# cyt2b6 register map
Vendor: Cypress Semiconductor; Series: cyt2b6; File version: 1.0
CPU: CM4 r0p1, little endian, MPU, FPU, VTOR, 3 interrupt priority bits
Registers are 32-bit, read-write, reset 0x0 unless marked. A register's access mark holds for its fields unless they carry their own. Offsets are from the block's base; [hi:lo] are bit positions; lines under a group give offsets from that group; {n}, {i} and the like mark numbered series; 'fields as' and 'values as' point back to an identical list; <NAME> marks a mode.

## SRSS (part 1 of 2) — SRSS Core Registers (ver2)
Base 0x40260000
0x40 PWR_LVD_STATUS ro — High Voltage / Low Voltage Detector (HVLVD) Status Register
  [0] HVLVD1_OUT — HVLVD1 output. 0: below voltage threshold 1: above voltage threshold
0x44 PWR_LVD_STATUS2 ro — High Voltage / Low Voltage Detector (HVLVD) Status Register #2
  [0] HVLVD2_OUT — HVLVD2 output. 0: below voltage threshold 1: above voltage threshold
{0x100+4i} CLK_DSI_SELECT[{i}] (i=0..15) — Clock DSI Select Register
  [4:0] DSI_MUX — Selects a DSI source or low frequency clock for use in a clock path. The output of this mux can be selected for clock PATH<i> using CLK_SELECT_PATH register. Using the output of this mux as HFCLK source will result in undefined behavior. It can be used to clocks to DSI or as reference inputs for the FLL/PLL, subject to the frequency limits of those circuits. This mux is not glitch free, so do not change the selection while it is an actively selected clock.
    {v}=DSI_OUT{v} (DSI{v} - dsi_out[{v}]) (v=0..15); 16=ILO0 (ILO0 - Internal Low-speed Oscillator #0); 17=WCO (WCO - Watch-Crystal Oscillator); 18=ALTLF (ALTLF - Alternate Low-Frequency Clock); 19=PILO (PILO - Precision Internal Low-speed Oscillator); 20=ILO1 (ILO1 - Internal Low-speed Oscillator #1, if present.)
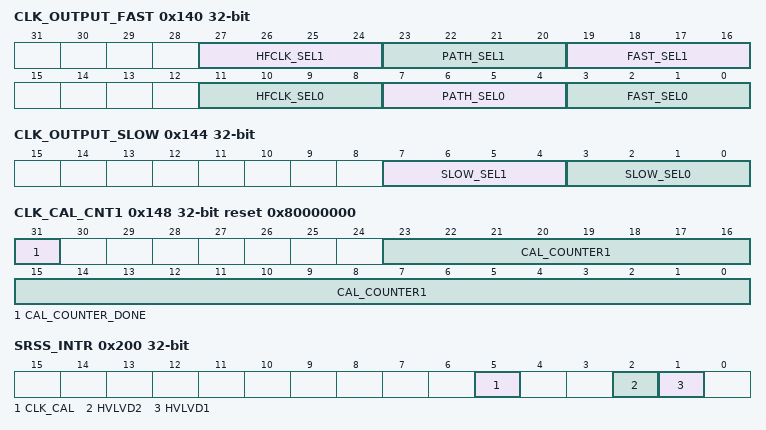
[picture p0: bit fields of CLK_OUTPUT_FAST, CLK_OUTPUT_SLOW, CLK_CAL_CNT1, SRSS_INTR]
0x140 CLK_OUTPUT_FAST — Fast Clock Output Select Register
  [27:24] HFCLK_SEL1 — Selects a HFCLK tree for use in fast clock output #1 logic
  [23:20] PATH_SEL1 — Selects a clock path to use in fast clock output #1 logic. 0: FLL output 1-15: PLL output on path1-path15 (if available)
  [19:16] FAST_SEL1 — Select signal for fast clock output #1
    0=NC (Disabled - output is 0. For power savings, clocks are blocked before entering any muxes, including PATH_SEL1 and HFCLK_SEL1.); 1=ECO (External Crystal Oscillator (ECO)); 2=EXTCLK (External clock input (EXTCLK)); 3=ALTHF (Alternate High-Frequency (ALTHF) clock input to SRSS); 4=TIMERCLK (Timer clock. It is grouped with the fast clocks because it may be a gated version of a fast clock, and therefore may have a short high pulse.); 5=PATH_SEL1 (Selects the clock path chosen by PATH_SEL1 field); 6=HFCLK_SEL1 (Selects the output of the HFCLK_SEL1 mux); 7=SLOW_SEL1 (Selects the output of CLK_OUTPUT_SLOW.SLOW_SEL1)
  [11:8] HFCLK_SEL0 — Selects a HFCLK tree for use in fast clock output #0
  [7:4] PATH_SEL0 — Selects a clock path to use in fast clock output #0 logic. 0: FLL output 1-15: PLL output on path1-path15 (if available)
  [3:0] FAST_SEL0 — Select signal for fast clock output #0
    0=NC (Disabled - output is 0. For power savings, clocks are blocked before entering any muxes, including PATH_SEL0 and HFCLK_SEL0.); 1=ECO (External Crystal Oscillator (ECO)); 2=EXTCLK (External clock input (EXTCLK)); 3=ALTHF (Alternate High-Frequency (ALTHF) clock input to SRSS); 4=TIMERCLK (Timer clock. It is grouped with the fast clocks because it may be a gated version of a fast clock, and therefore may have a short high pulse.); 5=PATH_SEL0 (Selects the clock path chosen by PATH_SEL0 field); 6=HFCLK_SEL0 (Selects the output of the HFCLK_SEL0 mux); 7=SLOW_SEL0 (Selects the output of CLK_OUTPUT_SLOW.SLOW_SEL0)
0x144 CLK_OUTPUT_SLOW — Slow Clock Output Select Register
  [7:4] SLOW_SEL1 — Select signal for slow clock output #1
    0=NC (Disabled - output is 0. For power savings, clocks are blocked before entering any muxes.); 1=ILO0 (Internal Low Speed Oscillator (ILO)); 2=WCO (Watch-Crystal Oscillator (WCO)); 3=BAK (Root of the Backup domain clock tree (BAK)); 4=ALTLF (Alternate low-frequency clock input to SRSS (ALTLF)); 5=LFCLK (Root of the low-speed clock tree (LFCLK)); 6=IMO (Internal Main Oscillator (IMO). This is grouped with the slow clocks so it can be observed during DEEPSLEEP entry/exit.); 7=SLPCTRL (Sleep Controller clock (SLPCTRL). This is grouped with the slow clocks so it can be observed during DEEPSLEEP entry/exit.); 8=PILO (Precision Internal Low Speed Oscillator (PILO)); 9=ILO1 (Internal Low Speed Oscillator (ILO1), if present on the product.); 10=ECO_PRESCALER (ECO Prescaler (ECO_PRESCALER))
  [3:0] SLOW_SEL0 — Select signal for slow clock output #0
    0=NC (Disabled - output is 0. For power savings, clocks are blocked before entering any muxes.); 1=ILO0 (Internal Low Speed Oscillator (ILO0)); 2=WCO (Watch-Crystal Oscillator (WCO)); 3=BAK (Root of the Backup domain clock tree (BAK)); 4=ALTLF (Alternate low-frequency clock input to SRSS (ALTLF)); 5=LFCLK (Root of the low-speed clock tree (LFCLK)); 6=IMO (Internal Main Oscillator (IMO). This is grouped with the slow clocks so it can be observed during DEEPSLEEP entry/exit.); 7=SLPCTRL (Sleep Controller clock (SLPCTRL). This is grouped with the slow clocks so it can be observed during DEEPSLEEP entry/exit.); 8=PILO (Precision Internal Low Speed Oscillator (PILO)); 9=ILO1 (Internal Low Speed Oscillator (ILO1), if present on the product.); 10=ECO_PRESCALER (ECO Prescaler (ECO_PRESCALER))
0x148 CLK_CAL_CNT1 reset 0x80000000 — Clock Calibration Counter 1
  [31] CAL_COUNTER_DONE ro — Status bit indicating that the internal counter #1 is finished counting and CLK_CAL_CNT2.COUNTER stopped counting up
  [23:0] CAL_COUNTER1 — Down-counter clocked on fast clock output #0 (see CLK_OUTPUT_FAST). This register always reads as zero. Counting starts internally when this register is written with a nonzero value. CAL_COUNTER_DONE goes immediately low to indicate that the counter has started and will be asserted when the counters are done. Do not write this field unless CAL_COUNTER_DONE==1. Both clocks must be running or the measurement will not complete. A stalled counter can be recovered by selecting valid clocks, waiting until the measurement completes, and discarding the first result.
0x14C CLK_CAL_CNT2 ro — Clock Calibration Counter 2
  [23:0] CAL_COUNTER2 — Up-counter clocked on fast clock output #1 (see CLK_OUTPUT_FAST). When CLK_CAL_CNT1.CAL_COUNTER_DONE==1, the counter is stopped and can be read by SW. Do not read this value unless CAL_COUNTER_DONE==1. The expected final value is related to the ratio of clock frequencies used for the two counters and the value loaded into counter 1: CLK_CAL_CNT2.COUNTER=(F_cnt2/F_cnt1)*(CLK_CAL_CNT1.COUNTER)
0x200 SRSS_INTR — SRSS Interrupt Register
  [5] CLK_CAL — Clock calibration counter is done. This field is reset during DEEPSLEEP mode.
  [2] HVLVD2 — Interrupt for low voltage detector HVLVD2
  [1] HVLVD1 — Interrupt for low voltage detector HVLVD1
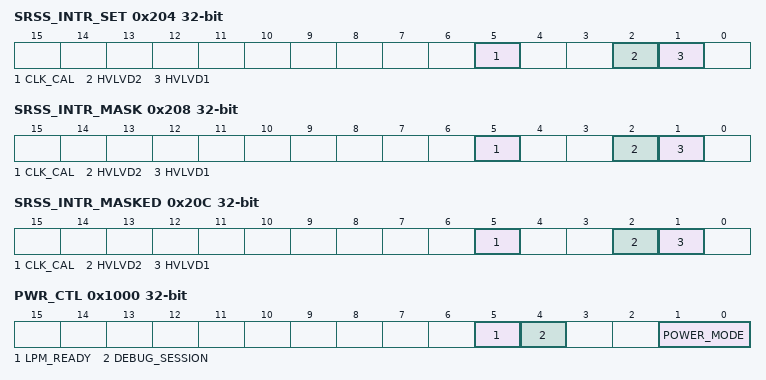
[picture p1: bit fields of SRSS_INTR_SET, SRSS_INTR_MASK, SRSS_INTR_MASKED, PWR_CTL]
0x204 SRSS_INTR_SET — SRSS Interrupt Set Register
  [5] CLK_CAL — Set interrupt for clock calibration counter done. This field is reset during DEEPSLEEP mode.
  [2] HVLVD2 — Set interrupt for low voltage detector HVLVD2
  [1] HVLVD1 — Set interrupt for low voltage detector HVLVD1
0x208 SRSS_INTR_MASK — SRSS Interrupt Mask Register
  [5] CLK_CAL — Mask for clock calibration done
  [2] HVLVD2 — Mask for low voltage detector HVLVD2
  [1] HVLVD1 — Mask for low voltage detector HVLVD1
0x20C SRSS_INTR_MASKED ro — SRSS Interrupt Masked Register
  [5] CLK_CAL — Logical and of corresponding request and mask bits.
  [2] HVLVD2 — Logical and of corresponding request and mask bits.
  [1] HVLVD1 — Logical and of corresponding request and mask bits.
0x1000 PWR_CTL ro — Power Mode Control
  [5] LPM_READY — Indicates whether certain low power functions are ready. The low current circuits take longer to startup after XRES, HIBERNATE wakeup, or supply supervision reset than the normal mode circuits. HIBERNATE mode may be entered regardless of this bit. This register is only reset by XRES, HIBERNATE wakeup, or supply supervision reset. 0: If a low power circuit operation is requested, it will stay in its normal operating mode until it is ready. If DEEPSLEEP is requested by all processors WFI/WFE, the device will instead enter SLEEP. When low power circuits are ready, device will automatically enter the originally requested mode. 1: Normal operation. DEEPSLEEP and low power circuits operate as requested in other registers.
  [4] DEBUG_SESSION — Indicates whether a debug session is active (CDBGPWRUPREQ signal is 1)
    0=NO_SESSION (No debug session active); 1=SESSION_ACTIVE (Debug session is active. Power modes behave differently to keep the debug session active.)
  [1:0] POWER_MODE — Current power mode of the device. Note that this field cannot be read in all power modes on actual silicon.
    0=RESET (System is resetting.); 1=ACTIVE (At least one CPU is running.); 2=SLEEP (No CPUs are running. Peripherals may be running.); 3=DEEPSLEEP (Main high-frequency clock is off; low speed clocks are available. Communication interface clocks may be present.)
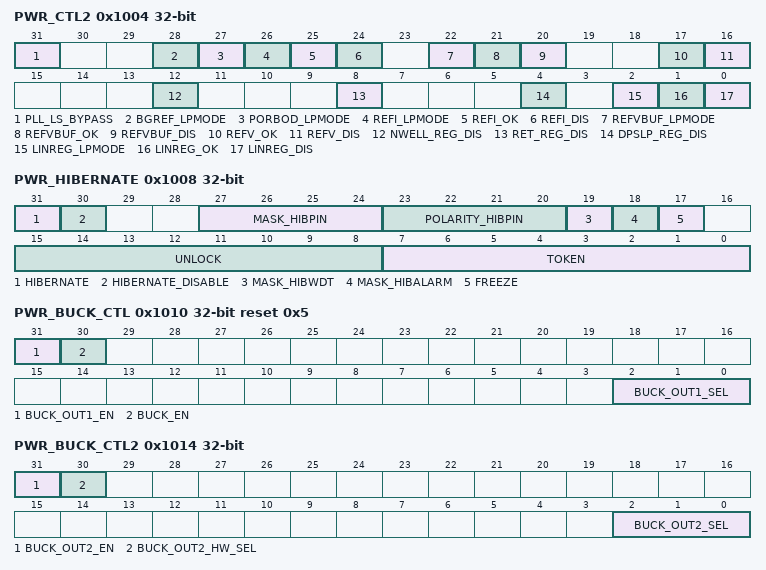
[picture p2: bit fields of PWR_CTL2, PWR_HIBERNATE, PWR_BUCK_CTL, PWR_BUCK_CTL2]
0x1004 PWR_CTL2 — Power Mode Control 2
  [31] PLL_LS_BYPASS — Bypass level shifter inside the PLL. Unused, if no PLL is present in the product. 0: Do not bypass the level shifter. This setting is ok for all operational modes and vccd target voltage. 1: Bypass the level shifter. This may reduce jitter on the PLL output clock, but can only be used when vccd is targeted to 1.1V nominal. Otherwise, it can result in clock degradation and static current.
  [28] BGREF_LPMODE — Current is reduced using a sample&hold feature. This requires ILO0 to be operating properly. This register will not set unless CLK_ILO0_CONFIG.ILO0_ENABLE==1. When changing back to continuous operation, keep ILO0 enabled for at least 5 cycles after clearing this bit to allow for internal synchronization. 0: Bandgap Reference circuits operate in higher current mode. 1: Bandgap Reference circuits operate in low power (see above for tradeoffs).
  [27] PORBOD_LPMODE — Control the power mode of the POR/BOD circuits. The value in this register is ignored and normal mode is used until LPM_READY==1. 0: POR/BOD circuits operate in normal mode. They work for vddd ramp rates of 100mV/us or less. 1: POR/BOD circuits operate in low power mode. Response time is reduced to save current, and they work for vddd ramp rates of 10mV/us or less.
  [26] REFI_LPMODE — Control the power mode of the reference current generator. The value in this register is ignored and normal mode is used until LPM_READY==1. 0: Current reference generator operates in normal mode. It works for vddd ramp rates of 100mV/us or less. 1: Current reference generator operates in low power mode. Response time is reduced to save current, and it works for vddd ramp rates of 10mV/us or less.
  [25] REFI_OK ro — Indicates that the current reference is ready. Due to synchronization delays, it may take two IMO clock cycles for hardware to clear this bit after asserting REFI_DIS=1.
  [24] REFI_DIS
  [22] REFVBUF_LPMODE — Control the power mode of the 800mV voltage reference buffer. The value in this register is ignored and normal mode is used until LPM_READY==1. 0: Voltage Reference Buffer operates in normal mode. They work for vddd ramp rates of 100mV/us or less. This register is only reset by XRES, HIBERNATE wakeup, or supply supervision reset. 1: Voltage Reference Buffer operates in low power mode. Power supply rejection is reduced to save current, and they work for vddd ramp rates of 10mV/us or less.
  [21] REFVBUF_OK ro — Indicates that the voltage reference buffer is ready. Due to synchronization delays, it may take two IMO clock cycles for hardware to clear this bit after asserting REFVBUF_DIS=1.
  [20] REFVBUF_DIS — Disable the voltage reference buffer. Firmware should only disable the buffer when there is no connected circuit that is using it. SRSS circuits that require it are the PLL and ECO. A particular product may have circuits outside the SRSS that use the buffer. This register is only reset by XRES, HIBERNATE wakeup, or supply supervision reset.
  [17] REFV_OK ro — Indicates that the normal mode of the voltage reference is ready.
  [16] REFV_DIS
  [12] NWELL_REG_DIS — Disable the Nwell regulator. This is only legal when another source supplies vnwell, but there is no special hardware protection for this case. This register is only reset by XRES, HIBERNATE wakeup, or supply supervision reset. 0: Nwell Regulator is on. 1: Nwell Regulator is off.
  [8] RET_REG_DIS — Disable the Retention regulator. This is only legal when another source supplies vccret, but there is no special hardware protection for this case. This register is only reset by XRES, HIBERNATE wakeup, or supply supervision reset. 0: Retention Regulator is on. 1: Retention Regulator is off.
  [4] DPSLP_REG_DIS
  [2] LINREG_LPMODE — Control the power mode of the Linear Regulator. The value in this register is ignored and normal mode is used until LPM_READY==1. 0: Linear Regulator operates in normal mode. Internal current consumption is 50uA and load current capability is 50mA to 300mA, depending on the number of regulator modules present in the product. 1: Linear Regulator operates in low power mode. Internal current consumption is 5uA and load current capability is 25mA. Firmware must ensure the current is kept within the limit.
  [1] LINREG_OK ro — Status of the linear Core Regulator.
  [0] LINREG_DIS — Explicitly disable the linear Core Regulator. Write zero for Traveo II devices. This register is only reset by XRES, HIBERNATE wakeup, or supply supervision reset. 0: Linear Core Regulator is not explicitly disabled. Hardware disables it automatically for internal sequences, including for DEEPSLEEP, HIBERNATE, and XRES low power modes. 1: Linear Core Regulator is explicitly disabled. Only use this for special cases when another source supplies vccd during ACTIVE and SLEEP modes. This setting is only legal when another source supplies vccd, but there is no special hardware protection for this case.
0x1008 PWR_HIBERNATE — HIBERNATE Mode Register
  [31] HIBERNATE — Firmware sets this bit to enter HIBERNATE mode. The system will enter HIBERNATE mode immediately after writing to this bit and will wakeup only in response to XRES or WAKEUP event. Both UNLOCK and FREEZE must have been set correctly in a previous write operations. Otherwise, it will not enter HIBERNATE. External supplies must have been stable for 250us before entering HIBERNATE mode.
  [30] HIBERNATE_DISABLE — Hibernate disable bit. 0: Normal operation, HIBERNATE works as described 1: Further writes to this register are ignored Note: This bit is a write-once bit until the next reset. Avoid changing any other bits in this register while disabling HIBERNATE mode. Also, it is recommended to clear the UNLOCK code, if it was previously written..
  [27:24] MASK_HIBPIN — When set, HIBERNATE will wakeup if the corresponding pin input matches the POLARITY_HIBPIN setting. Each bit corresponds to one of the wakeup pins.
  [23:20] POLARITY_HIBPIN — Each bit sets the active polarity of the corresponding wakeup pin. 0: Pin input of 0 will wakeup the part from HIBERNATE 1: Pin input of 1 will wakeup the part from HIBERNATE
  [19] MASK_HIBWDT — When set, HIBERNATE will wakeup for WDT interrupt
  [18] MASK_HIBALARM — When set, HIBERNATE will wakeup for a RTC interrupt
  [17] FREEZE — Firmware sets this bit to freeze the configuration, mode and state of all GPIOs and SIOs in the system. When entering HIBERNATE mode, the first write instructs DEEPSLEEP peripherals that they cannot ignore the upcoming freeze command. This occurs even in the illegal condition where UNLOCK is not set. If UNLOCK and HIBERNATE are properly set, the IOs actually freeze on the second write. Supply supervision is disabled during HIBERNATE mode. HIBERNATE peripherals ignore resets (excluding XRES) while FREEZE==1.
  [15:8] UNLOCK — This byte must be set to 0x3A for FREEZE or HIBERNATE fields to operate. Any other value in this register will cause FREEZE/HIBERNATE to have no effect, except as noted in the FREEZE description.
  [7:0] TOKEN — Contains a 8-bit token that is retained through a HIBERNATE/WAKEUP sequence that can be used by firmware to differentiate WAKEUP from a general RESET event. Note that waking up from HIBERNATE using XRES will reset this register.
0x1010 PWR_BUCK_CTL reset 0x5 — SIMO Buck Control Register
  [31] BUCK_OUT1_EN — Enable for vccbuck1 output. The value in this register is ignored unless PWR_BUCK_CTL.BUCK_EN==1. This register is only reset by XRES, HIBERNATE wakeup, or supply supervision reset. The regulator takes up to 600us to charge the external capacitor. If there is additional load current while charging, this will increase the startup time. The TRM specifies the required sequence when transitioning vccd from the LDO to SIMO Buck output #1.
  [30] BUCK_EN — Master enable for buck converter. This register is only reset by XRES, HIBERNATE wakeup, or supply supervision reset.
  [2:0] BUCK_OUT1_SEL — Voltage output selection for vccbuck1 output. This register is only reset by XRES, HIBERNATE wakeup, or supply supervision reset. When increasing the voltage, it can take up to 200us for the output voltage to settle. When decreasing the voltage, the settling time depends on the load current. 0: 0.85V 1: 0.875V 2: 0.90V 3: 0.95V 4: 1.05V 5: 1.10V 6: 1.15V 7: 1.20V
0x1014 PWR_BUCK_CTL2 — SIMO Buck Control Register 2
  [31] BUCK_OUT2_EN — Enable for vccbuck2 output. The value in this register is ignored unless PWR_BUCK_CTL.BUCK_EN==1. The regulator takes up to 600us to charge the external capacitor. If there is additional load current while charging, this will increase the startup time.
  [30] BUCK_OUT2_HW_SEL — Hardware control for vccbuck2 output. When this bit is set, the value in BUCK_OUT2_EN is ignored and a hardware signal is used instead. If the product has supporting hardware, it can directly control the enable signal for vccbuck2. The same charging time in BUCK_OUT2_EN applies.
  [2:0] BUCK_OUT2_SEL — Voltage output selection for vccbuck2 output. When increasing the voltage, it can take up to 200us for the output voltage to settle. When decreasing the voltage, the settling time depends on the load current. 0: 1.15V 1: 1.20V 2: 1.25V 3: 1.30V 4: 1.35V 5: 1.40V 6: 1.45V 7: 1.50V
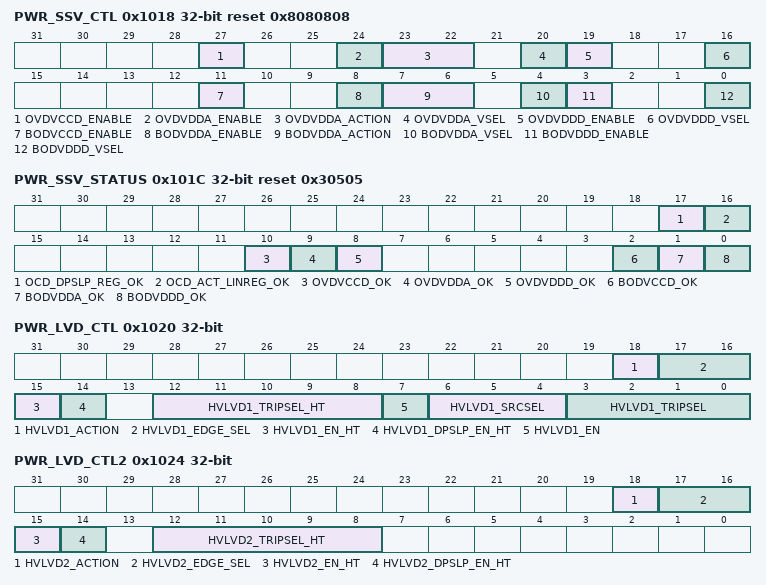
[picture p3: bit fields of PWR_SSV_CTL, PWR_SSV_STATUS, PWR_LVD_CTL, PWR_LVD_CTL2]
0x1018 PWR_SSV_CTL reset 0x8080808 — Supply Supervision Control Register
  [27] OVDVCCD_ENABLE — Enable for OVD on vccd. This cannot be disabled during normal operation.
  [24] OVDVDDA_ENABLE — Enable for OVD on vdda.
  [23:22] OVDVDDA_ACTION — Action taken when the OVD on vdda triggers.
    0=NOTHING (No action); 1=FAULT (Generate a fault); 2=RESET (Reset the chip)
  [20] OVDVDDA_VSEL — Selects the voltage threshold for OVD on vdda. Ensure OVDVDDA_ENABLE==0 before changing this setting to prevent false triggers 0: vddd>5.5V 1: vddd>5.0V
  [19] OVDVDDD_ENABLE — Enable for OVD on vddd. This cannot be disabled during normal operation.
  [16] OVDVDDD_VSEL — Selects the voltage threshold for OVD on vddd. The OVD does not reliably monitor the supply during the transition. 0: vddd>5.5V 1: vddd>5.0V
  [11] BODVCCD_ENABLE — Enable for BOD on vccd. This cannot be disabled during normal operation.
  [8] BODVDDA_ENABLE — Enable for BOD on vdda. BODVDDA_ACTION will be triggered when the BOD is disabled. If no action is desired when disabling, firmware must first write BODVDDA_ACTION=NOTHING in a separate write cycle.
  [7:6] BODVDDA_ACTION — Action taken when the BOD on vdda triggers.
    values as OVDVDDA_ACTION
  [4] BODVDDA_VSEL — Selects the voltage threshold for BOD on vdda. Ensure BODVDDA_ENABLE==0 before changing this setting to prevent false triggers. 0: vdda<2.7V 1: vdda<3.0V
  [3] BODVDDD_ENABLE — Enable for BOD on vddd. This cannot be disabled during normal operation.
  [0] BODVDDD_VSEL — Selects the voltage threshold for BOD on vddd. The BOD does not reliably monitor the supply during the transition. 0: vddd<2.7V 1: vddd<3.0V
0x101C PWR_SSV_STATUS ro reset 0x30505 — Supply Supervision Status Register
  [17] OCD_DPSLP_REG_OK — OCD indicates the current drawn from the linear DeepSleep Regulator is ok. This will always read 1, because a detected over-current condition will reset the chip.
  [16] OCD_ACT_LINREG_OK — OCD indicates the current drawn from the linear Active Regulator is ok. This will always read 1, because a detected over-current condition will reset the chip.
  [10] OVDVCCD_OK — OVD indicates vccd is ok. This will always read 1, because a detected over-over-voltage condition will reset the chip.
  [9] OVDVDDA_OK — OVD indicates vdda is ok.
  [8] OVDVDDD_OK — OVD indicates vddd is ok. This will always read 1, because a detected over-voltage condition will reset the chip.
  [2] BODVCCD_OK — BOD indicates vccd is ok. This will always read 1, because a detected brownout will reset the chip.
  [1] BODVDDA_OK — BOD indicates vdda is ok.
  [0] BODVDDD_OK — BOD indicates vddd is ok. This will always read 1, because a detected brownout will reset the chip.
0x1020 PWR_LVD_CTL — High Voltage / Low Voltage Detector (HVLVD) Configuration Register
  [18] HVLVD1_ACTION — Action taken when the threshold is crossed in the programmed directions(s)
    0=INTERRUPT (Generate an interrupt); 1=FAULT (Generate a fault)
  [17:16] HVLVD1_EDGE_SEL — Sets which edge(s) will trigger an action when the threshold is crossed.
    0=DISABLE (Disabled); 1=RISING (Rising edge); 2=FALLING (Falling edge); 3=BOTH (Both rising and falling edges)
  [15] HVLVD1_EN_HT — Enable HVLVD1 voltage monitor. This detector monitors vddd only. Do not change other HVLVD1 settings when enabled.
  [14] HVLVD1_DPSLP_EN_HT — Keep HVLVD1 voltage monitor enabled during DEEPSLEEP mode. This field is only used when HVLVD1_EN_HT==1.
  [12:8] HVLVD1_TRIPSEL_HT
  [7] HVLVD1_EN — Enable HVLVD1 voltage monitor. HVLVD1 does not function during DEEPSLEEP, but it automatically returns to its configured setting after DEEPSLEEP wakeup. Do not change other HVLVD1 settings when enabled.
  [6:4] HVLVD1_SRCSEL — Source selection for HVLVD1
    0=VDDD (Select VDDD); 1=AMUXBUSA (Select AMUXBUSA (VDDD branch)); 2=RSVD (N/A); 3=VDDIO (N/A); 4=AMUXBUSB (Select AMUXBUSB (VDDD branch))
  [3:0] HVLVD1_TRIPSEL — Threshold selection for HVLVD1 for products. Disable the detector (HVLVD1_EN=0) before changing the threshold. 0: rise=1.225V (nom), fall=1.2V (nom) 1: rise=1.425V (nom), fall=1.4V (nom) 2: rise=1.625V (nom), fall=1.6V (nom) 3: rise=1.825V (nom), fall=1.8V (nom) 4: rise=2.025V (nom), fall=2V (nom) 5: rise=2.125V (nom), fall=2.1V (nom) 6: rise=2.225V (nom), fall=2.2V (nom) 7: rise=2.325V (nom), fall=2.3V (nom) 8: rise=2.425V (nom), fall=2.4V (nom) 9: rise=2.525V (nom), fall=2.5V (nom) 10: rise=2.625V (nom), fall=2.6V (nom) 11: rise=2.725V (nom), fall=2.7V (nom) 12: rise=2.825V (nom), fall=2.8V (nom) 13: rise=2.925V (nom), fall=2.9V (nom) 14: rise=3.025V (nom), fall=3.0V (nom) 15: rise=3.125V (nom), fall=3.1V (nom)
0x1024 PWR_LVD_CTL2 — High Voltage / Low Voltage Detector (HVLVD) Configuration Register #2
  [18] HVLVD2_ACTION — Action taken when the threshold is crossed in the programmed directions(s)
    values as PWR_LVD_CTL.HVLVD1_ACTION
  [17:16] HVLVD2_EDGE_SEL — Sets which edge(s) will trigger an action when the threshold is crossed.
    values as PWR_LVD_CTL.HVLVD1_EDGE_SEL
  [15] HVLVD2_EN_HT — Enable HVLVD2 voltage monitor. This detector monitors vddd only. Do not change other HVLVD2 settings when enabled.
  [14] HVLVD2_DPSLP_EN_HT — Keep HVLVD2 voltage monitor enabled during DEEPSLEEP mode. This field is only used when HVLVD1_EN_HT==1.
  [12:8] HVLVD2_TRIPSEL_HT
{0x1040+4i} PWR_HIB_DATA[{i}] (i=0..15) — HIBERNATE Data Register
  [31:0] HIB_DATA — Additional data that is retained through a HIBERNATE/WAKEUP sequence that can be used by firmware for any application-specific purpose. Note that waking up from HIBERNATE using XRES will reset this register.
{0x1200+4i} CLK_PATH_SELECT[{i}] (i=0..15) — Clock Path Select Register
  [2:0] PATH_MUX — Selects a source for clock PATH<i>. Note that not all products support all clock sources. Selecting a clock source that is not supported will result in undefined behavior. It takes four cycles of the originally selected clock to switch away from it. Do not disable the original clock during this time.
    0=IMO (IMO - Internal R/C Oscillator); 1=EXTCLK (EXTCLK - External Clock Pin); 2=ECO (ECO - External-Crystal Oscillator); 3=ALTHF (ALTHF - Alternate High-Frequency clock input (product-specific clock)); 4=DSI_MUX (DSI_MUX - Output of DSI mux for this path. Using a DSI source directly as root of HFCLK will result in undefined behavior.); 5=LPECO (N/A)
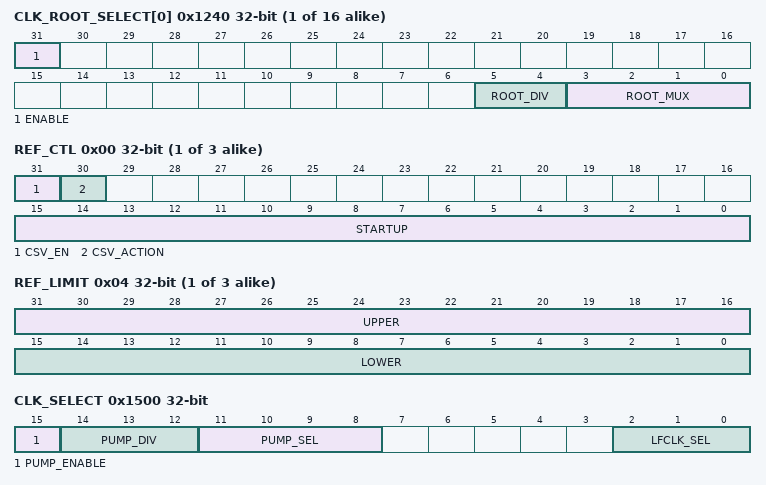
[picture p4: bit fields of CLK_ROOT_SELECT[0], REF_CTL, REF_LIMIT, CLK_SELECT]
{0x1240+4i} CLK_ROOT_SELECT[{i}] (i=0..15) — Clock Root Select Register
  [31] ENABLE — Enable for this clock root. All clock roots default to disabled (ENABLE==0) except HFCLK0, which cannot be disabled.
  [5:4] ROOT_DIV — Selects predivider value for this clock root and DSI input.
    0=NO_DIV (Transparent mode, feed through selected clock source w/o dividing.); 1=DIV_BY_2 (Divide selected clock source by 2); 2=DIV_BY_4 (Divide selected clock source by 4); 3=DIV_BY_8 (Divide selected clock source by 8)
  [3:0] ROOT_MUX — Selects a clock path as the root of HFCLK<k> and for SRSS DSI input <k>. Use CLK_SELECT_PATH[i] to configure the desired path. Some paths may have FLL or PLL available (product-specific), and the control and bypass mux selections of these are in other registers. Configure the FLL using CLK_FLL_CONFIG register. Configure a PLL using the related CLK_PLL_CONFIG[k] register. Note that not all products support all clock sources. Selecting a clock source that is not supported will result in undefined behavior. It takes four cycles of the originally selected clock to switch away from it. Do not disable the original clock during this time.
    0=PATH0 (Select PATH0 (can be configured for FLL)); {v}=PATH{v} (Select PATH{v} (can be configured for PLL{v-1}, if available in the product)) (v=1..15)
0x1400 CSV_HF group — Clock Supervisor (CSV) registers for Root clocks
  {0x0+0x10*j} CSV[{j}] (j=0..2) group — Active domain Clock Supervisor (CSV) registers
    0x00 REF_CTL — Clock Supervision Reference Control
      [31] CSV_EN — Enables clock supervision, both frequency and loss. CSV in Active domain: Clock supervision is reset during DeepSleep and Hibernate modes. When enabled it begins operating automatically after a DeepSleep wakeup, but it must be reconfigured after Hibernate wakeup. CSV in DeepSleep domain: Clock supervision is reset during Hibernate mode. It must be reconfigured after Hibernate wakeup. A CSV error detection is reported to the Fault structure, or instead it can generate a power reset.
      [30] CSV_ACTION — Specifies the action taken when an anomaly is detected on the monitored clock. CSV in DeepSleep domain always do a Fault report (which also wakes up the system).
        0=FAULT (Do a Fault report.); 1=RESET (Cause a power reset. This should only be used for clk_hf0.)
      [15:0] STARTUP — Startup delay time -1 (in reference clock cycles), after enable or DeepSleep wakeup, from reference clock start to monitored clock start. At a minimum (both clocks running): STARTUP >= (PERIOD +3) * FREQ_RATIO - UPPER, with FREQ_RATIO = (Reference frequency / Monitored frequency) On top of that the actual clock startup delay and the margin for accuracy of both clocks must be added.
    0x04 REF_LIMIT — Clock Supervision Reference Limits
      [31:16] UPPER — Cycle time upper limit. Set the upper limit -1, in reference clock cycles, before (or same time) the next monitored clock event must happen. If a monitored clock event does not happen before this limit is reached, or does not happen at all (clock loss), a CSV error is detected.
      [15:0] LOWER — Cycle time lower limit. Set the lower limit -1, in reference clock cycles, before the next monitored clock event is allowed to happen. If a monitored clock event happens before this limit is reached a CSV error is detected. LOWER must be at least 1 less than UPPER. In case the clocks are asynchronous LOWER must be at least 3 less than UPPER.
    0x08 MON_CTL — Clock Supervision Monitor Control
      [15:0] PERIOD — Period time. Set the Period -1, in monitored clock cycles, before the next monitored clock event happens. PERIOD <= (UPPER+1) / FREQ_RATIO -1, with FREQ_RATIO = (Reference frequency / Monitored frequency) In case the clocks are asynchronous: PERIOD <= UPPER / FREQ_RATIO -1 Additionally margin must be added for accuracy of both clocks.
0x1500 CLK_SELECT — Clock selection register
  [15] PUMP_ENABLE — Enable the pump clock. PUMP_ENABLE and the PUMP_SEL mux are not glitch-free to minimize side-effects, avoid changing the PUMP_SEL and PUMP_DIV while changing PUMP_ENABLE. To change the settings, do the following: 1) If the pump clock is enabled, write PUMP_ENABLE=0 without changing PUMP_SEL and PUMP_DIV. 2) Change PUMP_SEL and PUMP_DIV to desired settings with PUMP_ENABLE=0. 3) Write PUMP_ENABLE=1 without changing PUMP_SEL and PUMP_DIV.
  [14:12] PUMP_DIV — Division ratio for PUMPCLK. Uses selected PUMP_SEL clock as the source.
    0=NO_DIV (Transparent mode, feed through selected clock source w/o dividing.); 1=DIV_BY_2 (Divide selected clock source by 2); 2=DIV_BY_4 (Divide selected clock source by 4); 3=DIV_BY_8 (Divide selected clock source by 8); 4=DIV_BY_16 (Divide selected clock source by 16)
  [11:8] PUMP_SEL — Selects clock PATH<k>, where k=PUMP_SEL. The output of this mux goes to the PUMP_DIV to make PUMPCLK Each product has a specific number of available clock paths. Selecting a path that is not implemented on a product will result in undefined behavior. Note that this is not a glitch free mux.
  [2:0] LFCLK_SEL — Select source for LFCLK. Note that not all products support all clock sources. Selecting a clock source that is not supported will result in undefined behavior. Writes to this field are ignored unless the WDT is unlocked using WDT_LOCK register. It takes four cycles of the originally selected clock to switch away from it. Do not disable the original clock during this time.
    0=ILO0 (ILO0 - Internal Low-speed Oscillator #0.); 1=WCO (WCO - Watch-Crystal Oscillator. Requires Backup domain to be present and properly configured (including external watch crystal, if used).); 2=ALTLF (ALTLF - Alternate Low-Frequency Clock. Capability is product-specific); 3=PILO (PILO - Precision ILO. If present, it works in DEEPSLEEP and higher modes. Does not work in HIBERNATE mode.); 4=ILO1 (ILO1 - Internal Low-speed Oscillator #1, if present.); 5=ECO_PRESCALE (ECO_PRESCALE - External-Crystal Oscillator after prescaling in CLK_ECO_PRESCALE. Does not work in DEEPSLEEP or HIBERNATE modes. Intended for applications that operate in ACTIVE/SLEEP modes only. This option is only valid when an ECO present in the product.)
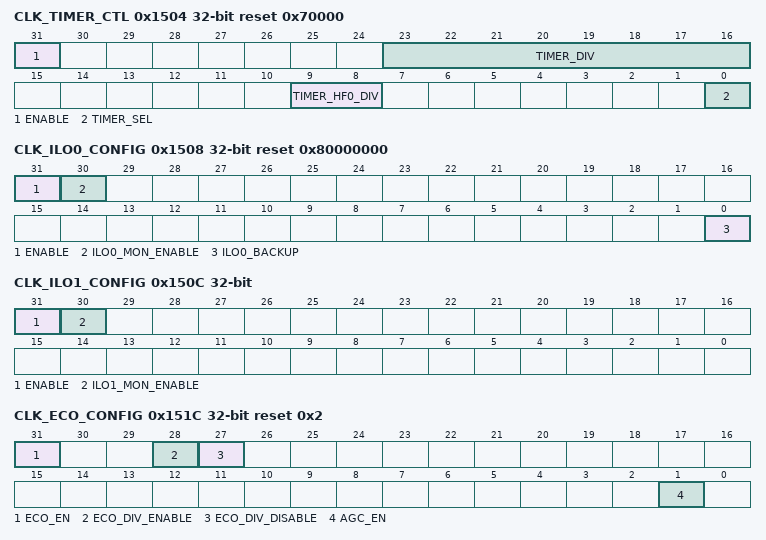
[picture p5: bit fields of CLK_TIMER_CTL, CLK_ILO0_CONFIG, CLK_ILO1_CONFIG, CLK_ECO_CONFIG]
0x1504 CLK_TIMER_CTL reset 0x70000 — Timer Clock Control Register
  [31] ENABLE — Enable for TIMERCLK. 0: TIMERCLK is off 1: TIMERCLK is enabled
  [23:16] TIMER_DIV — Divide selected timer clock source by (1+TIMER_DIV). The output of this divider is TIMERCLK Allows for integer divisions in the range [1, 256]. Do not change this setting while the timer is enabled.
  [9:8] TIMER_HF0_DIV — Predivider used when HF0_DIV is selected in TIMER_SEL. If HFCLK0 frequency is less than 100MHz and has approximately 50 percent duty cycle, then no division is required (NO_DIV). Otherwise, select a divide ratio of 2, 4, or 8 before selected HF0_DIV as the timer clock.
    0=NO_DIV (Transparent mode, feed through selected clock source w/o dividing or correcting duty cycle.); 1=DIV_BY_2 (Divide HFCLK0 by 2.); 2=DIV_BY_4 (Divide HFCLK0 by 4.); 3=DIV_BY_8 (Divide HFCLK0 by 8.)
  [0] TIMER_SEL — Select source for TIMERCLK. The output of this mux can be further divided using TIMER_DIV. It takes four cycles of the originally selected clock to switch away from it. Do not disable the original clock during this time.
    0=IMO (IMO - Internal Main Oscillator); 1=HF0_DIV (Select the output of the predivider configured by TIMER_HF0_DIV.)
0x1508 CLK_ILO0_CONFIG reset 0x80000000 — ILO0 Configuration
  [31] ENABLE — Master enable for ILO. Writes to this field are ignored unless the WDT is unlocked using WDT_LOCK register. HT-variant: This register will not clear unless PWR_CTL2.BGREF_LPMODE==0. After enabling, the first ILO0 cycle occurs within 12us and is +/-10 percent accuracy. Thereafter, ILO0 is +/-5 percent accurate.
  [30] ILO0_MON_ENABLE
  [0] ILO0_BACKUP — This register indicates that ILO0 should stay enabled during XRES and HIBERNATE modes. If backup voltage domain is implemented on the product, this bit also indicates if ILO0 should stay enabled through power-related resets on other supplies, e.g.. BOD on VDDD/VCCD. Writes to this field are ignored unless the WDT is unlocked using WDT_LOCK register. This register is reset when the backup logic resets. 0: ILO0 turns off during XRES, HIBERNATE, and power-related resets. ILO0 configuration and trims are reset by these events. 1: ILO0 stays enabled, as described above. ILO0 configuration and trims are not reset by these events.
0x150C CLK_ILO1_CONFIG — ILO1 Configuration
  [31] ENABLE — Master enable for ILO1. HT-variant: After enabling, the first ILO1 cycle occurs within 12us and is +/-10 percent accuracy. Thereafter, ILO1 is +/-5 percent accurate.
  [30] ILO1_MON_ENABLE
0x1518 CLK_IMO_CONFIG reset 0x80000000 — IMO Configuration
  [31] ENABLE — Master enable for IMO oscillator. This bit must be high at all times for all functions to work properly. Hardware will automatically disable the IMO during DEEPSLEEP, HIBERNATE, and XRES.
0x151C CLK_ECO_CONFIG reset 0x2 — ECO Configuration Register
  [31] ECO_EN — Master enable for ECO oscillator.
  [28] ECO_DIV_ENABLE — ECO prescaler enable command (mutually exclusive with ECO_DIV_DISABLE). ECO Prescaler only works in ACTIVE and SLEEP modes. SW sets this field to '1' to enable the divider and HW sets this field to '0' to indicate that divider enabling has completed. When the divider is enabled, its integer and fractional counters are initialized to '0'. If a divider is to be re-enabled using different integer and fractional divider values, the SW should follow these steps: 0: Disable the divider using the ECO_DIV_DISABLE field. 1: Configure CLK_ECO_PRESCALE registers. 2: Enable the divider using the ECO_DIV_ENABLE field. HW sets the ECO_DIV_ENABLE field to '0' when the enabling is performed and HW set CLK_ECO_PRESCALER.ENABLED to '1' when the enabling is performed.
  [27] ECO_DIV_DISABLE — ECO prescaler disable command (mutually exclusive with ECO_DIV_ENABLE). SW sets this field to '1' and HW sets this field to '0'. HW sets ECO_DIV_DISABLE field to '0' immediately and HW sets CLK_ECO_PRESCALE.ECO_DIV_EN field to '0' immediately.
  [1] AGC_EN — Automatic Gain Control (AGC) enable. When set, the oscillation amplitude is controlled to the level selected by CLK_ECO_CONFIG2.ATRIM. When low, the amplitude is not explicitly controlled and can be as high as the vddd supply. WARNING: use care when disabling AGC because driving a crystal beyond its rated limit can permanently damage the crystal.
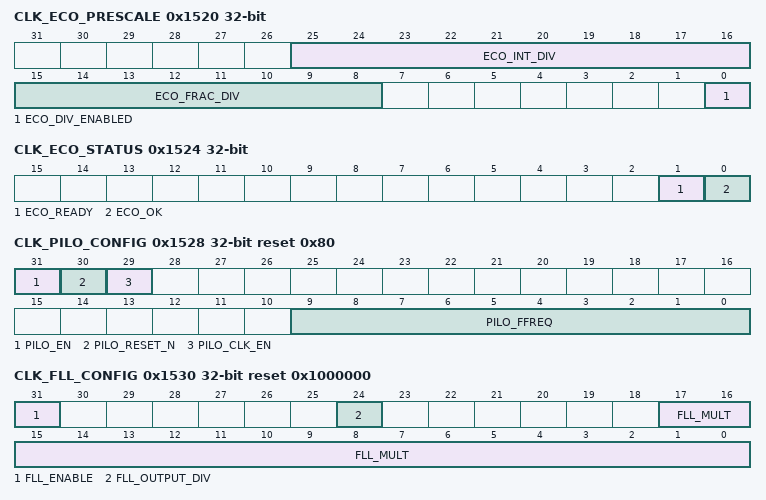
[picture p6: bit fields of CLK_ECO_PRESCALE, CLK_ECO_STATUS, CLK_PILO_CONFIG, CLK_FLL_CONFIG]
0x1520 CLK_ECO_PRESCALE — ECO Prescaler Configuration Register
  [25:16] ECO_INT_DIV — 10-bit integer value allows for ECO frequencies up to 33.55MHz. Subtract one from the desired divide value when writing this field. For example, to divide by 1, write ECO_INT_DIV=0. Do not change this setting when ECO Prescaler is enabled.
  [15:8] ECO_FRAC_DIV — 8-bit fractional value, sufficient to get prescaler output within the +/-65ppm calibration range. Do not change this setting when ECO Prescaler is enabled.
  [0] ECO_DIV_ENABLED ro — ECO prescaler enabled. HW sets this field to '1' as a result of an CLK_ECO_CONFIG.ECO_DIV_ENABLE command. HW sets this field to '0' as a result on a CLK_ECO_CONFIG.ECO_DIV_DISABLE command.
0x1524 CLK_ECO_STATUS ro — ECO Status Register
  [1] ECO_READY — Indicates the ECO internal oscillator circuit has had enough time to fully stabilize. This is the output of a counter since ECO was enabled, and it does not check the ECO output. It is recommended to also confirm ECO_OK==1.
  [0] ECO_OK — Indicates the ECO internal oscillator circuit has sufficient amplitude. It may not meet the PPM accuracy or duty cycle spec.
0x1528 CLK_PILO_CONFIG reset 0x80 — Precision ILO Configuration Register
  [31] PILO_EN — Enable PILO. When enabling PILO, set PILO_EN=1, wait 1ms, then PILO_RESET_N=1 and PILO_CLK_EN=1. When disabling PILO, clear PILO_EN=0, PILO_RESET_N=0, and PLO_CLK_EN=0 in the same write cycle.
  [30] PILO_RESET_N — Reset the PILO. See PILO_EN field for required sequencing.
  [29] PILO_CLK_EN — Enable the PILO clock output. See PILO_EN field for required sequencing.
  [9:0] PILO_FFREQ — Fine frequency trim allowing +/-250ppm accuracy with periodic calibration. The nominal step size of the LSB is 8Hz.
0x1530 CLK_FLL_CONFIG reset 0x1000000 — FLL Configuration Register
  [31] FLL_ENABLE — Master enable for FLL. The FLL requires firmware sequencing when enabling and disabling. Hardware handles sequencing automatically when entering/exiting DEEPSLEEP. To enable the FLL, use the following sequence: 1) Configure FLL and CCO settings. Do not modify CLK_FLL_CONFIG3.BYPASS_SEL (must be AUTO) or CLK_FLL_CONFIG.FLL_ENABLE (must be 0). 2) Enable the CCO by writing CLK_FLL_CONFIG4.CCO_ENABLE=1 3) Wait until CLK_FLL_STATUS.CCO_READY==1. 4) Ensure the reference clock has stabilized. 5) Write FLL_ENABLE=1. 6) Optionally wait until CLK_FLL_STATUS.LOCKED==1. The hardware automatically changes to the FLL output when LOCKED==1. To disable the FLL, use the following sequence: 1) Write CLK_FLL_CONFIG3.BYPASS_SEL=FLL_REF. 2) Read CLK_FLL_CONFIG3.BYPASS_SEL to ensure the write completes (read is not optional). 3) Wait at least ten cycles of either FLL reference clock or FLL output clock, whichever is slower. 4) Disable FLL with FLL_ENABLE=0. 5) Disable the CCO by writing CLK_FLL_CONFIG4.CCO_ENABLE=0. 6) Write CLK_FLL_CONFIG3.BYPASS_SEL=AUTO. 7) Read CLK_FLL_CONFIG3.BYPASS_SEL to ensure the write completes (read is not optional). 8) Wait three cycles of FLL reference clock. 0: Block is powered off 1: Block is powered on
  [24] FLL_OUTPUT_DIV — Control bits for Output divider. Set the divide value before enabling the FLL, and do not change it while FLL is enabled. 0: no division 1: divide by 2
  [17:0] FLL_MULT — Multiplier to determine CCO frequency in multiples of the frequency of the selected reference clock (Fref). Ffll = (FLL_MULT) * (Fref / REFERENCE_DIV) / (OUTPUT_DIV+1)
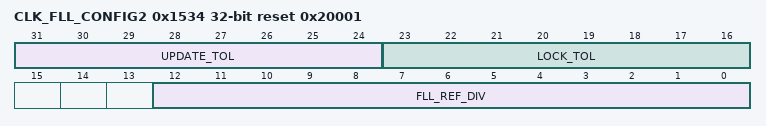
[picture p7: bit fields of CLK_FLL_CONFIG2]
0x1534 CLK_FLL_CONFIG2 reset 0x20001 — FLL Configuration Register 2
  [31:24] UPDATE_TOL — Update tolerance sets the error threshold for when the FLL will update the CCO frequency settings. The update tolerance is the allowed difference between the count value for the ideal formula and the measured value. UPDATE_TOL should be less than LOCK_TOL.
  [23:16] LOCK_TOL — Lock tolerance sets the error threshold for when the FLL output is considered locked to the reference input. A high tolerance can be used to lock more quickly or allow less accuracy. The tolerance is the allowed difference between the count value for the ideal formula and the measured value. 0: tolerate error of 1 count value 1: tolerate error of 2 count values ... 255: tolerate error of 256 count values
  [12:0] FLL_REF_DIV — Control bits for reference divider. Set the divide value before enabling the FLL, and do not change it while FLL is enabled. 0: illegal (undefined behavior) 1: divide by 1 ... 8191: divide by 8191

## Notices in the file
Copyright 2016-2019, Cypress Semiconductor Corporation.  All rights reserved.
You may use this file only in accordance with the license, terms, conditions,
disclaimers, and limitations in the end user license agreement accompanying
the software package with which this file was provided.
